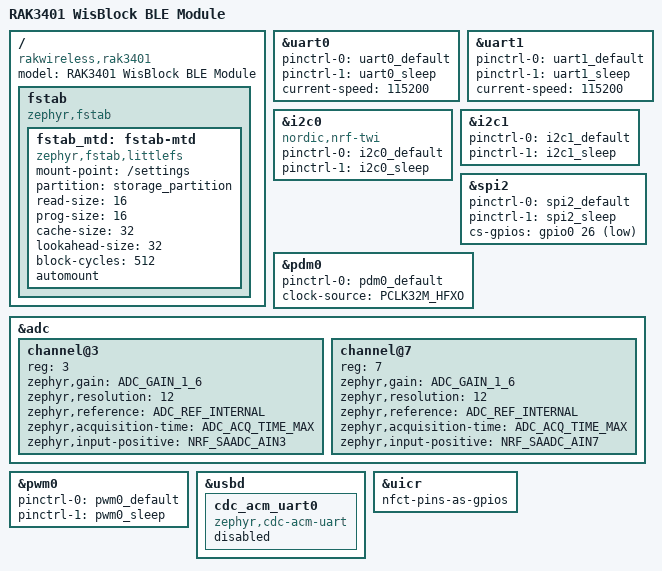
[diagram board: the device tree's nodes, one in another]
/*
 * SPDX-License-Identifier: Apache-2.0
 * Copyright (c) 2026 RAKwireless Technology Limited
 */

/dts-v1/;
#include <rakwireless/rak3400.dtsi>
#include "rak3401-pinctrl.dtsi"

/ {
        model = "RAK3401 WisBlock BLE Module";
        compatible = "rakwireless,rak3401";

	fstab {
		compatible = "zephyr,fstab";

		fstab_mtd: fstab-mtd {
			compatible = "zephyr,fstab,littlefs";
			mount-point = "/settings";
			partition = <&storage_partition>;
			read-size = <16>;
			prog-size = <16>;
			cache-size = <32>;
			lookahead-size = <32>;
			block-cycles = <512>;
			automount;
		};
	};
};

&uart0 {
	pinctrl-0 = <&uart0_default>;
	pinctrl-1 = <&uart0_sleep>;
	pinctrl-names = "default", "sleep";
	current-speed = <115200>;
};

&uart1 {
	pinctrl-0 = <&uart1_default>;
	pinctrl-1 = <&uart1_sleep>;
	pinctrl-names = "default", "sleep";
	current-speed = <115200>;
};

&i2c0 {
	compatible = "nordic,nrf-twi";
	pinctrl-0 = <&i2c0_default>;
	pinctrl-1 = <&i2c0_sleep>;
	pinctrl-names = "default", "sleep";
};

&i2c1 {
	pinctrl-0 = <&i2c1_default>;
	pinctrl-1 = <&i2c1_sleep>;
	pinctrl-names = "default", "sleep";
};

&spi2 {
	pinctrl-0 = <&spi2_default>;
	pinctrl-1 = <&spi2_sleep>;
	pinctrl-names = "default", "sleep";

	cs-gpios = <&gpio0 26 GPIO_ACTIVE_LOW>;
};

&pdm0 {
	pinctrl-0 = <&pdm0_default>;
	pinctrl-names = "default";
	clock-source = "PCLK32M_HFXO";
};

&adc {
	status = "okay";
	#address-cells = <1>;
	#size-cells = <0>;

	channel@3 {
		reg = <3>;
		zephyr,gain = "ADC_GAIN_1_6";
		zephyr,resolution = <12>;
		zephyr,reference = "ADC_REF_INTERNAL";
		zephyr,acquisition-time = <ADC_ACQ_TIME_MAX>;
		zephyr,input-positive = <NRF_SAADC_AIN3>;
	};

	channel@7 {
		reg = <7>;
		zephyr,gain = "ADC_GAIN_1_6";
		zephyr,resolution = <12>;
		zephyr,reference = "ADC_REF_INTERNAL";
		zephyr,acquisition-time = <ADC_ACQ_TIME_MAX>;
		zephyr,input-positive = <NRF_SAADC_AIN7>;
	};
};

&pwm0 {
	status = "okay";
	pinctrl-0 = <&pwm0_default>;
	pinctrl-1 = <&pwm0_sleep>;
	pinctrl-names = "default", "sleep";
};

zephyr_udc0: &usbd {
	status = "okay";

	cdc_acm_uart0: cdc_acm_uart0 {
		status = "disabled";
		compatible = "zephyr,cdc-acm-uart";
	};
};

&uicr {
	nfct-pins-as-gpios;
};

#include "wisblock.dtsi"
